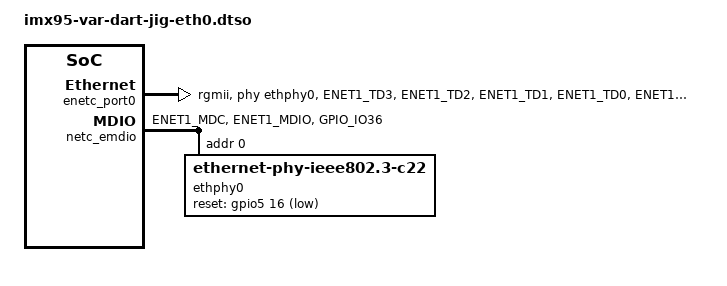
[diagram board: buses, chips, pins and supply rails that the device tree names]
// SPDX-License-Identifier: (GPL-2.0+ OR MIT)
/*
 * Copyright 2023 NXP
 * Copyright 2024 Variscite Ltd.
 */

#include <dt-bindings/gpio/gpio.h>
#include <dt-bindings/net/mxl-8611x.h>
#include <dt-bindings/net/qca-ar803x.h>
#include "imx95-pinfunc.h"

/dts-v1/;
/plugin/;
&enetc_port0 {
	pinctrl-names = "default";
	pinctrl-0 = <&pinctrl_enetc0>;
	phy-handle = <&ethphy0>;
	phy-mode = "rgmii";
	status = "okay";
};

&scmi_iomuxc {
	pinctrl_enetc0: enetc0grp {
		fsl,pins = <
			IMX95_PAD_ENET1_TD3__NETCMIX_TOP_ETH0_RGMII_TD3			0x57e
			IMX95_PAD_ENET1_TD2__NETCMIX_TOP_ETH0_RGMII_TD2			0x57e
			IMX95_PAD_ENET1_TD1__NETCMIX_TOP_ETH0_RGMII_TD1			0x57e
			IMX95_PAD_ENET1_TD0__NETCMIX_TOP_ETH0_RGMII_TD0			0x57e
			IMX95_PAD_ENET1_TX_CTL__NETCMIX_TOP_ETH0_RGMII_TX_CTL		0x57e
			IMX95_PAD_ENET1_TXC__NETCMIX_TOP_ETH0_RGMII_TX_CLK		0x58e
			IMX95_PAD_ENET1_RX_CTL__NETCMIX_TOP_ETH0_RGMII_RX_CTL		0x57e
			IMX95_PAD_ENET1_RXC__NETCMIX_TOP_ETH0_RGMII_RX_CLK		0x58e
			IMX95_PAD_ENET1_RD0__NETCMIX_TOP_ETH0_RGMII_RD0			0x57e
			IMX95_PAD_ENET1_RD1__NETCMIX_TOP_ETH0_RGMII_RD1			0x57e
			IMX95_PAD_ENET1_RD2__NETCMIX_TOP_ETH0_RGMII_RD2			0x57e
			IMX95_PAD_ENET1_RD3__NETCMIX_TOP_ETH0_RGMII_RD3			0x57e
		>;
	};

	pinctrl_emdio: emdiogrp{
		fsl,pins = <
			IMX95_PAD_ENET1_MDC__NETCMIX_TOP_NETC_MDC			0x57e
			IMX95_PAD_ENET1_MDIO__NETCMIX_TOP_NETC_MDIO			0x97e
		>;
	};

	pinctrl_phy0res: phy0resgrp{
		fsl,pins = <
			IMX95_PAD_GPIO_IO36__GPIO5_IO_BIT16				0x31e
		>;
	};
};

&netc_emdio {
	pinctrl-names = "default";
	pinctrl-0 = <&pinctrl_emdio>, <&pinctrl_phy0res>;
	status = "okay";

	ethphy0: ethernet-phy@0 {
		reg = <0>;
		compatible = "ethernet-phy-ieee802.3-c22";
		reset-gpios = <&gpio5 16 GPIO_ACTIVE_LOW>;
		reset-assert-us = <10000>;
		reset-deassert-us = <100000>;

		mxl-8611x,led0_cfg = <(
			MXL8611X_LEDX_CFG_LINK_UP_RX_ACT_ON |
			MXL8611X_LEDX_CFG_LINK_UP_TX_ACT_ON |
			MXL8611X_LEDX_CFG_TRAFFIC_ACT_BLINK_IND
		)>;
		mxl-8611x,led1_cfg = <(
			MXL8611X_LEDX_CFG_LINK_UP_10MB_ON |
			MXL8611X_LEDX_CFG_LINK_UP_100MB_ON |
			MXL8611X_LEDX_CFG_LINK_UP_1GB_ON
		)>;
	};
};
